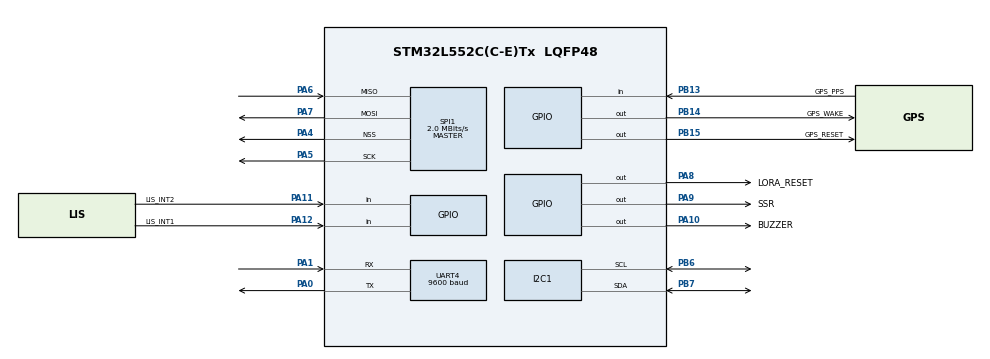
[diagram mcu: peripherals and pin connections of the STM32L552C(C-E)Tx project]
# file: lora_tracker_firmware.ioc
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Mcu.Family=STM32L5
PA6.Mode=Full_Duplex_Master
SPI1.VirtualType=VM_MASTER
PH0-OSC_IN\ (PH0).Signal=RCC_OSC_IN
PB14.GPIO_Label=GPS_WAKE
VP_RTC_VS_RTC_Activate.Mode=RTC_Enabled
PA15\ (JTDI).Signal=DEBUG_JTDI
PC15-OSC32_OUT\ (PC15).Mode=LSE-External-Oscillator
PB13.GPIO_Label=GPS_PPS
PB13.Signal=GPIO_Input
PB15.Signal=GPIO_Output
ProjectManager.StackSize=0x400
PC14-OSC32_IN\ (PC14).Mode=LSE-External-Oscillator
PA14\ (JTCK/SWCLK).Signal=DEBUG_JTCK-SWCLK
PA15\ (JTDI).Mode=JTAG_5_pins
PA12.Signal=GPIO_Input
PA4.Mode=NSS_Signal_Hard_Output
SPI1.Direction=SPI_DIRECTION_2LINES
UART4.BaudRate=9600
PB6.Signal=I2C1_SCL
PB6.Mode=I2C
SPI1.CalculateBaudRate=2.0 MBits/s
PH1-OSC_OUT\ (PH1).Mode=HSE-External-Oscillator
RCC.HSE_VALUE=16000000
PA10.GPIO_Label=BUZZER
PA0.Mode=Multiprocessor_communication
PB7.Signal=I2C1_SDA
PA8.Signal=GPIO_Output
PA14\ (JTCK/SWCLK).Mode=JTAG_5_pins
SPI1.VirtualNSS=VM_NSSHARD
PA0.Signal=UART4_TX
Mcu.Package=LQFP48
PA6.Signal=SPI1_MISO
PA10.Signal=GPIO_Output
VP_RTC_VS_RTC_Calendar.Mode=RTC_Calendar
VP_PWR_VS_DBSignals.Mode=DisableDeadBatterySignals
PH0-OSC_IN\ (PH0).Mode=HSE-External-Oscillator
RCC.HSI48_VALUE=48000000
PA5.Mode=Full_Duplex_Master
RCC.MSI_VALUE=4000000
PA7.Mode=Full_Duplex_Master
PA13\ (JTMS/SWDIO).Mode=JTAG_5_pins
PA9.GPIO_Label=SSR
PA11.GPIO_Label=LIS_INT2
PC15-OSC32_OUT\ (PC15).Signal=RCC_OSC32_OUT
PA12.GPIO_Label=LIS_INT1
PH1-OSC_OUT\ (PH1).Signal=RCC_OSC_OUT
PA8.GPIO_Label=LORA_RESET
PB3\ (JTDO/TRACESWO).Signal=DEBUG_JTDO-SWO
ProjectManager.TargetToolchain=STM32CubeIDE
PA9.Signal=GPIO_Output
PA1.Signal=UART4_RX
PB14.Signal=GPIO_Output
PA5.Signal=SPI1_SCK
board=custom
RCC.VCOOutputFreq_Value=32000000
PA1.Mode=Multiprocessor_communication
PB15.GPIO_Label=GPS_RESET
SPI1.Mode=SPI_MODE_MASTER
PB4\ (NJTRST).Mode=JTAG_5_pins
Mcu.Name=STM32L552C(C-E)Tx
VP_ICACHE_VS_ICACHE.Mode=DefaultMode
PA4.Signal=SPI1_NSS
PC14-OSC32_IN\ (PC14).Signal=RCC_OSC32_IN
PB7.Mode=I2C
PA11.Signal=GPIO_Input
ProjectManager.HeapSize=0x200
RCC.HSI_VALUE=16000000
NVIC.PriorityGroup=NVIC_PRIORITYGROUP_3
PB3\ (JTDO/TRACESWO).Mode=JTAG_5_pins
PA13\ (JTMS/SWDIO).Signal=DEBUG_JTMS-SWDIO
PA7.Signal=SPI1_MOSI
PB4\ (NJTRST).Signal=DEBUG_JTRST

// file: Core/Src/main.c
/* USER CODE BEGIN Header */
/**
  ******************************************************************************
  * @file           : main.c
  * @brief          : Main program body
  ******************************************************************************
  * @attention
  *
  * <h2><center>&copy; Copyright (c) 2021 STMicroelectronics.
  * All rights reserved.</center></h2>
  *
  * This software component is licensed by ST under BSD 3-Clause license,
  * the "License"; You may not use this file except in compliance with the
  * License. You may obtain a copy of the License at:
  *                        opensource.org/licenses/BSD-3-Clause
  *
  ******************************************************************************
  */
/* USER CODE END Header */
#include "main.h"

/* USER CODE BEGIN Includes */
#include <gps.h>
/* USER CODE END Includes */

I2C_HandleTypeDef hi2c1;

RTC_HandleTypeDef hrtc;

SPI_HandleTypeDef hspi1;

UART_HandleTypeDef huart4;

void SystemClock_Config(void);
static void MX_GPIO_Init(void);
static void MX_I2C1_Init(void);
static void MX_RTC_Init(void);
static void MX_SPI1_Init(void);
static void MX_UART4_Init(void);
static void MX_ICACHE_Init(void);

int main(void)
{

  /* MCU Configuration--------------------------------------------------------*/

  /* Reset of all peripherals, Initializes the Flash interface and the Systick. */
  HAL_Init();

  /* Configure the system clock */
  SystemClock_Config();

  /* Initialize all configured peripherals */
  MX_GPIO_Init();
  MX_I2C1_Init();
  MX_RTC_Init();
  MX_SPI1_Init();
  MX_UART4_Init();
  MX_ICACHE_Init();

  /* Infinite loop */
  while (1)
  {

  }
}

void SystemClock_Config(void)
{
  RCC_OscInitTypeDef RCC_OscInitStruct = {0};
  RCC_ClkInitTypeDef RCC_ClkInitStruct = {0};

  /** Configure the main internal regulator output voltage
  */
  if (HAL_PWREx_ControlVoltageScaling(PWR_REGULATOR_VOLTAGE_SCALE2) != HAL_OK)
  {
    Error_Handler();
  }
  /** Initializes the RCC Oscillators according to the specified parameters
  * in the RCC_OscInitTypeDef structure.
  */
  RCC_OscInitStruct.OscillatorType = RCC_OSCILLATORTYPE_LSI|RCC_OSCILLATORTYPE_MSI;
  RCC_OscInitStruct.LSIDiv = RCC_LSI_DIV1;
  RCC_OscInitStruct.LSIState = RCC_LSI_ON;
  RCC_OscInitStruct.MSIState = RCC_MSI_ON;
  RCC_OscInitStruct.MSICalibrationValue = RCC_MSICALIBRATION_DEFAULT;
  RCC_OscInitStruct.MSIClockRange = RCC_MSIRANGE_6;
  RCC_OscInitStruct.PLL.PLLState = RCC_PLL_NONE;
  if (HAL_RCC_OscConfig(&RCC_OscInitStruct) != HAL_OK)
  {
    Error_Handler();
  }
  /** Initializes the CPU, AHB and APB buses clocks
  */
  RCC_ClkInitStruct.ClockType = RCC_CLOCKTYPE_HCLK|RCC_CLOCKTYPE_SYSCLK
                              |RCC_CLOCKTYPE_PCLK1|RCC_CLOCKTYPE_PCLK2;
  RCC_ClkInitStruct.SYSCLKSource = RCC_SYSCLKSOURCE_MSI;
  RCC_ClkInitStruct.AHBCLKDivider = RCC_SYSCLK_DIV1;
  RCC_ClkInitStruct.APB1CLKDivider = RCC_HCLK_DIV1;
  RCC_ClkInitStruct.APB2CLKDivider = RCC_HCLK_DIV1;

  if (HAL_RCC_ClockConfig(&RCC_ClkInitStruct, FLASH_LATENCY_0) != HAL_OK)
  {
    Error_Handler();
  }
}

static void MX_I2C1_Init(void)
{

  hi2c1.Instance = I2C1;
  hi2c1.Init.Timing = 0x00000E14;
  hi2c1.Init.OwnAddress1 = 0;
  hi2c1.Init.AddressingMode = I2C_ADDRESSINGMODE_7BIT;
  hi2c1.Init.DualAddressMode = I2C_DUALADDRESS_DISABLE;
  hi2c1.Init.OwnAddress2 = 0;
  hi2c1.Init.OwnAddress2Masks = I2C_OA2_NOMASK;
  hi2c1.Init.GeneralCallMode = I2C_GENERALCALL_DISABLE;
  hi2c1.Init.NoStretchMode = I2C_NOSTRETCH_DISABLE;
  if (HAL_I2C_Init(&hi2c1) != HAL_OK)
  {
    Error_Handler();
  }
  /** Configure Analogue filter
  */
  if (HAL_I2CEx_ConfigAnalogFilter(&hi2c1, I2C_ANALOGFILTER_ENABLE) != HAL_OK)
  {
    Error_Handler();
  }
  /** Configure Digital filter
  */
  if (HAL_I2CEx_ConfigDigitalFilter(&hi2c1, 0) != HAL_OK)
  {
    Error_Handler();
  }

}

static void MX_ICACHE_Init(void)
{

  /** Enable instruction cache (default 2-ways set associative cache)
  */
  if (HAL_ICACHE_Enable() != HAL_OK)
  {
    Error_Handler();
  }

}

static void MX_RTC_Init(void)
{

  RTC_PrivilegeStateTypeDef privilegeState = {0};
  RTC_TimeTypeDef sTime = {0};
  RTC_DateTypeDef sDate = {0};

  /** Initialize RTC Only
  */
  hrtc.Instance = RTC;
  hrtc.Init.HourFormat = RTC_HOURFORMAT_24;
  hrtc.Init.AsynchPrediv = 127;
  hrtc.Init.SynchPrediv = 255;
  hrtc.Init.OutPut = RTC_OUTPUT_DISABLE;
  hrtc.Init.OutPutRemap = RTC_OUTPUT_REMAP_NONE;
  hrtc.Init.OutPutPolarity = RTC_OUTPUT_POLARITY_HIGH;
  hrtc.Init.OutPutType = RTC_OUTPUT_TYPE_OPENDRAIN;
  hrtc.Init.OutPutPullUp = RTC_OUTPUT_PULLUP_NONE;
  if (HAL_RTC_Init(&hrtc) != HAL_OK)
  {
    Error_Handler();
  }
  privilegeState.rtcPrivilegeFull = RTC_PRIVILEGE_FULL_NO;
  privilegeState.backupRegisterPrivZone = RTC_PRIVILEGE_BKUP_ZONE_NONE;
  privilegeState.backupRegisterStartZone2 = RTC_BKP_DR0;
  privilegeState.backupRegisterStartZone3 = RTC_BKP_DR0;
  if (HAL_RTCEx_PrivilegeModeSet(&hrtc, &privilegeState) != HAL_OK)
  {
    Error_Handler();
  }

  /** Initialize RTC and set the Time and Date
  */
  sTime.Hours = 0x0;
  sTime.Minutes = 0x0;
  sTime.Seconds = 0x0;
  sTime.DayLightSaving = RTC_DAYLIGHTSAVING_NONE;
  sTime.StoreOperation = RTC_STOREOPERATION_RESET;
  if (HAL_RTC_SetTime(&hrtc, &sTime, RTC_FORMAT_BCD) != HAL_OK)
  {
    Error_Handler();
  }
  sDate.WeekDay = RTC_WEEKDAY_MONDAY;
  sDate.Month = RTC_MONTH_JANUARY;
  sDate.Date = 0x1;
  sDate.Year = 0x0;

  if (HAL_RTC_SetDate(&hrtc, &sDate, RTC_FORMAT_BCD) != HAL_OK)
  {
    Error_Handler();
  }

}

static void MX_SPI1_Init(void)
{

  /* SPI1 parameter configuration*/
  hspi1.Instance = SPI1;
  hspi1.Init.Mode = SPI_MODE_MASTER;
  hspi1.Init.Direction = SPI_DIRECTION_2LINES;
  hspi1.Init.DataSize = SPI_DATASIZE_4BIT;
  hspi1.Init.CLKPolarity = SPI_POLARITY_LOW;
  hspi1.Init.CLKPhase = SPI_PHASE_1EDGE;
  hspi1.Init.NSS = SPI_NSS_HARD_OUTPUT;
  hspi1.Init.BaudRatePrescaler = SPI_BAUDRATEPRESCALER_2;
  hspi1.Init.FirstBit = SPI_FIRSTBIT_MSB;
  hspi1.Init.TIMode = SPI_TIMODE_DISABLE;
  hspi1.Init.CRCCalculation = SPI_CRCCALCULATION_DISABLE;
  hspi1.Init.CRCPolynomial = 7;
  hspi1.Init.CRCLength = SPI_CRC_LENGTH_DATASIZE;
  hspi1.Init.NSSPMode = SPI_NSS_PULSE_ENABLE;
  if (HAL_SPI_Init(&hspi1) != HAL_OK)
  {
    Error_Handler();
  }

}

static void MX_UART4_Init(void)
{

  huart4.Instance = UART4;
  huart4.Init.BaudRate = 9600;
  huart4.Init.WordLength = UART_WORDLENGTH_8B;
  huart4.Init.StopBits = UART_STOPBITS_1;
  huart4.Init.Parity = UART_PARITY_NONE;
  huart4.Init.Mode = UART_MODE_TX_RX;
  huart4.Init.HwFlowCtl = UART_HWCONTROL_NONE;
  huart4.Init.OverSampling = UART_OVERSAMPLING_16;
  huart4.Init.OneBitSampling = UART_ONE_BIT_SAMPLE_DISABLE;
  huart4.Init.ClockPrescaler = UART_PRESCALER_DIV1;
  huart4.AdvancedInit.AdvFeatureInit = UART_ADVFEATURE_NO_INIT;
  if (HAL_MultiProcessor_Init(&huart4, 0, UART_WAKEUPMETHOD_IDLELINE) != HAL_OK)
  {
    Error_Handler();
  }
  if (HAL_UARTEx_SetTxFifoThreshold(&huart4, UART_TXFIFO_THRESHOLD_1_8) != HAL_OK)
  {
    Error_Handler();
  }
  if (HAL_UARTEx_SetRxFifoThreshold(&huart4, UART_RXFIFO_THRESHOLD_1_8) != HAL_OK)
  {
    Error_Handler();
  }
  if (HAL_UARTEx_DisableFifoMode(&huart4) != HAL_OK)
  {
    Error_Handler();
  }

}

static void MX_GPIO_Init(void)
{
  GPIO_InitTypeDef GPIO_InitStruct = {0};

  /* GPIO Ports Clock Enable */
  __HAL_RCC_GPIOC_CLK_ENABLE();
  __HAL_RCC_GPIOH_CLK_ENABLE();
  __HAL_RCC_GPIOA_CLK_ENABLE();
  __HAL_RCC_GPIOB_CLK_ENABLE();

  /*Configure GPIO pin Output Level */
  HAL_GPIO_WritePin(GPIOB, GPS_WAKE_Pin|GPS_RESET_Pin, GPIO_PIN_RESET);

  /*Configure GPIO pin Output Level */
  HAL_GPIO_WritePin(GPIOA, LORA_RESET_Pin|SSR_Pin|BUZZER_Pin, GPIO_PIN_RESET);

  /*Configure GPIO pin : GPS_PPS_Pin */
  GPIO_InitStruct.Pin = GPS_PPS_Pin;
  GPIO_InitStruct.Mode = GPIO_MODE_INPUT;
  GPIO_InitStruct.Pull = GPIO_NOPULL;
  HAL_GPIO_Init(GPS_PPS_GPIO_Port, &GPIO_InitStruct);

  /*Configure GPIO pins : GPS_WAKE_Pin GPS_RESET_Pin */
  GPIO_InitStruct.Pin = GPS_WAKE_Pin|GPS_RESET_Pin;
  GPIO_InitStruct.Mode = GPIO_MODE_OUTPUT_PP;
  GPIO_InitStruct.Pull = GPIO_NOPULL;
  GPIO_InitStruct.Speed = GPIO_SPEED_FREQ_LOW;
  HAL_GPIO_Init(GPIOB, &GPIO_InitStruct);

  /*Configure GPIO pins : LORA_RESET_Pin SSR_Pin BUZZER_Pin */
  GPIO_InitStruct.Pin = LORA_RESET_Pin|SSR_Pin|BUZZER_Pin;
  GPIO_InitStruct.Mode = GPIO_MODE_OUTPUT_PP;
  GPIO_InitStruct.Pull = GPIO_NOPULL;
  GPIO_InitStruct.Speed = GPIO_SPEED_FREQ_LOW;
  HAL_GPIO_Init(GPIOA, &GPIO_InitStruct);

  /*Configure GPIO pins : LIS_INT2_Pin LIS_INT1_Pin */
  GPIO_InitStruct.Pin = LIS_INT2_Pin|LIS_INT1_Pin;
  GPIO_InitStruct.Mode = GPIO_MODE_INPUT;
  GPIO_InitStruct.Pull = GPIO_NOPULL;
  HAL_GPIO_Init(GPIOA, &GPIO_InitStruct);

}

void Error_Handler(void)
{
  __disable_irq();
  while (1)
  {
  }
}

/************************ (C) COPYRIGHT STMicroelectronics *****END OF FILE****/
